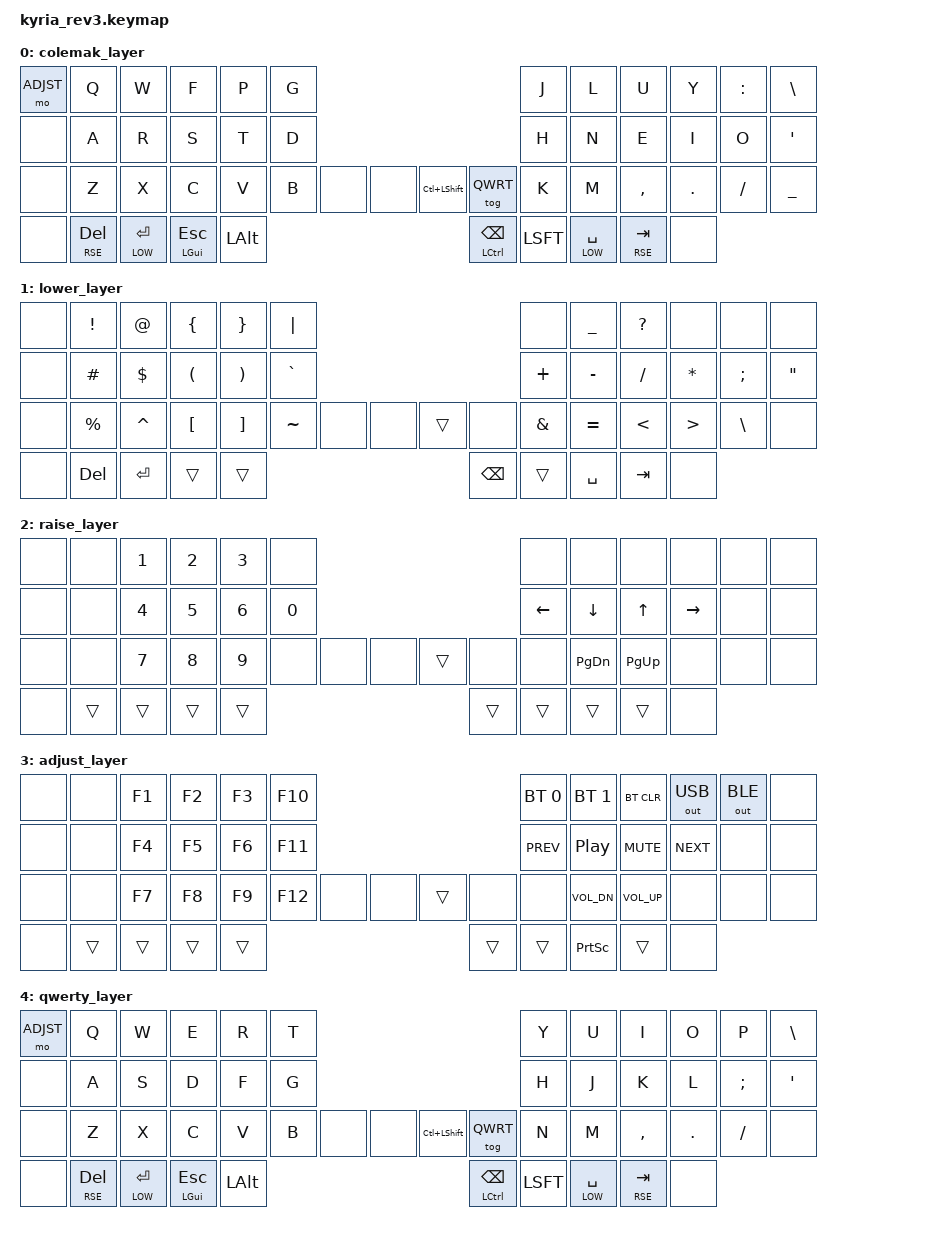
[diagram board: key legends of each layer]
/* vim: ft=c
 * Copyright (c) 2023 The ZMK Contributors
 *
 * SPDX-License-Identifier: MIT
 */

#include <behaviors.dtsi>
#include <dt-bindings/zmk/keys.h>
#include <dt-bindings/zmk/outputs.h>
#include <dt-bindings/zmk/bt.h>

#define COLMK 0
#define LOW 1
#define RSE 2
#define ADJST 3
#define QWRT 4

#define TAP_TERM_MS 120
// TODO maybe enable but make sure everything else works first
#define QUICK_TAP_MS 0
#define TAP_FLAVOR "tap-preferred"

/ {
    behaviors {
        htx: hold_tap {
            compatible = "zmk,behavior-hold-tap";
            label = "HOLD_TAP";
            #binding-cells = <2>;
            flavor = TAP_FLAVOR;
            tapping-term-ms = <TAP_TERM_MS>;
            quick-tap-ms = <QUICK_TAP_MS>;
            bindings = <&kp>, <&kp>;
        };
        ltx: layer_tap {
            compatible = "zmk,behavior-hold-tap";
            label = "LAYER_TAP";
            #binding-cells = <2>;
            flavor = TAP_FLAVOR;
            tapping-term-ms = <TAP_TERM_MS>;
            quick-tap-ms = <QUICK_TAP_MS>;
            bindings = <&mo>, <&kp>;
        };
    };

    keymap {
        compatible = "zmk,keymap";

        colemak_layer {
            bindings = <
            &mo ADJST &kp Q     &kp W     &kp F     &kp P     &kp G                                                    &kp J     &kp L     &kp U     &kp Y     &kp COLON &kp BSLH
            &none     &kp A     &kp R     &kp S     &kp T     &kp D                                                    &kp H     &kp N     &kp E     &kp I     &kp O     &kp SQT
            &none     &kp Z     &kp X     &kp C     &kp V     &kp B     &none     &none        &kp LC(LSHFT) &tog QWRT &kp K     &kp M     &kp COMMA &kp DOT   &kp FSLH  &kp UNDER

            &none  &ltx RSE DEL &ltx LOW RET &htx LGUI ESC &kp LALT                                &htx LCTRL BSPC &kp LSFT &ltx LOW SPACE &ltx RSE TAB &none
            >;
        };

        lower_layer {
            bindings = <
            &none     &kp EXCL  &kp AT    &kp LBRC  &kp RBRC  &kp PIPE                                                 &none     &kp UNDER &kp QMARK &none     &none     &none   
            &none     &kp HASH  &kp DLLR  &kp LPAR  &kp RPAR  &kp GRAVE                                                &kp PLUS  &kp MINUS &kp FSLH  &kp STAR  &kp SEMI  &kp DQT
            &none     &kp PRCNT &kp CARET &kp LBKT  &kp RBKT  &kp TILDE &none     &none            &trans    &none     &kp AMPS  &kp EQUAL &kp LT    &kp GT    &kp BSLH  &none

            &none  &kp DEL     &kp RET     &trans          &trans                                  &kp BSPC          &trans   &kp SPACE     &kp TAB     &none
            >;
        };

        raise_layer {
            bindings = <
            &none     &none     &kp N1    &kp N2    &kp N3    &none                                                    &none     &none     &none     &none     &none     &none   
            &none     &none     &kp N4    &kp N5    &kp N6    &kp N0                                                   &kp LEFT  &kp DOWN  &kp UP    &kp RIGHT &none     &none
            &none     &none     &kp N7    &kp N8    &kp N9    &none     &none     &none            &trans    &none     &none     &kp PG_DN &kp PG_UP &none     &none     &none

            &none  &trans      &trans      &trans          &trans                                  &trans            &trans   &trans        &trans      &none
            >;
        };

        adjust_layer {
            bindings = <
            &none     &none     &kp F1    &kp F2    &kp F3    &kp F10                                                  &bt BT_SEL 0 &bt BT_SEL 1 &bt BT_CLR &out OUT_USB &out OUT_BLE &none   
            &none     &none     &kp F4    &kp F5    &kp F6    &kp F11                                                  &kp C_PREV &kp C_PP  &kp C_MUTE&kp C_NEXT &none     &none
            &none     &none     &kp F7    &kp F8    &kp F9    &kp F12   &none     &none            &trans    &none     &none     &kp C_VOL_DN &kp C_VOL_UP &none     &none     &none

            &none  &trans      &trans      &trans          &trans                                  &trans            &trans   &kp PSCRN     &trans      &none
            >;
        };

        qwerty_layer {
            bindings = <
            &mo ADJST &kp Q     &kp W     &kp E     &kp R     &kp T                                                    &kp Y     &kp U     &kp I     &kp O     &kp P     &kp BSLH
            &none     &kp A     &kp S     &kp D     &kp F     &kp G                                                    &kp H     &kp J     &kp K     &kp L     &kp SEMI  &kp SQT
            &none     &kp Z     &kp X     &kp C     &kp V     &kp B     &none     &none         &kp LC(LSHFT) &tog QWRT &kp N     &kp M     &kp COMMA &kp DOT   &kp FSLH  &none

            &none  &ltx RSE DEL &ltx LOW RET &htx LGUI ESC &kp LALT                                &htx LCTRL BSPC &kp LSFT &ltx LOW SPACE &ltx RSE TAB &none
            >;
        };
    };
};
